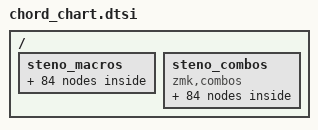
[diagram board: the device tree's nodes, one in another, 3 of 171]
#include "keypos.h"

/ {
    steno_macros {
      m_examples_: m_examples_ {
        compatible = "zmk,behavior-macro";
        #binding-cells = <0>;
        wait-ms = <0>;
        tap-ms = <10>;
        bindings = <&macro_tap &kp E &kp X &kp A &kp M &kp P &kp L &kp E &kp S &kp SPACE>;
      };

      m_example_: m_example_ {
        compatible = "zmk,behavior-macro";
        #binding-cells = <0>;
        wait-ms = <0>;
        tap-ms = <10>;
        bindings = <&macro_tap &kp E &kp X &kp A &kp M &kp P &kp L &kp E &kp SPACE>;
      };

      m_languages_: m_languages_ {
        compatible = "zmk,behavior-macro";
        #binding-cells = <0>;
        wait-ms = <0>;
        tap-ms = <10>;
        bindings = <&macro_tap &kp L &kp A &kp N &kp G &kp U &kp A &kp G &kp E &kp S &kp SPACE>;
      };

      m_language_: m_language_ {
        compatible = "zmk,behavior-macro";
        #binding-cells = <0>;
        wait-ms = <0>;
        tap-ms = <10>;
        bindings = <&macro_tap &kp L &kp A &kp N &kp G &kp U &kp A &kp G &kp E &kp SPACE>;
      };

      m_logical_: m_logical_ {
        compatible = "zmk,behavior-macro";
        #binding-cells = <0>;
        wait-ms = <0>;
        tap-ms = <10>;
        bindings = <&macro_tap &kp L &kp O &kp G &kp I &kp C &kp A &kp L &kp SPACE>;
      };

      m_whichever_: m_whichever_ {
        compatible = "zmk,behavior-macro";
        #binding-cells = <0>;
        wait-ms = <0>;
        tap-ms = <10>;
        bindings = <&macro_tap &kp W &kp H &kp I &kp C &kp H &kp E &kp V &kp E &kp R &kp SPACE>;
      };

      m_which_: m_which_ {
        compatible = "zmk,behavior-macro";
        #binding-cells = <0>;
        wait-ms = <0>;
        tap-ms = <10>;
        bindings = <&macro_tap &kp W &kp H &kp I &kp C &kp H &kp SPACE>;
      };

      m_screens_: m_screens_ {
        compatible = "zmk,behavior-macro";
        #binding-cells = <0>;
        wait-ms = <0>;
        tap-ms = <10>;
        bindings = <&macro_tap &kp S &kp C &kp R &kp E &kp E &kp N &kp S &kp SPACE>;
      };

      m_screened_: m_screened_ {
        compatible = "zmk,behavior-macro";
        #binding-cells = <0>;
        wait-ms = <0>;
        tap-ms = <10>;
        bindings = <&macro_tap &kp S &kp C &kp R &kp E &kp E &kp N &kp E &kp D &kp SPACE>;
      };

      m_screening_: m_screening_ {
        compatible = "zmk,behavior-macro";
        #binding-cells = <0>;
        wait-ms = <0>;
        tap-ms = <10>;
        bindings = <&macro_tap &kp S &kp C &kp R &kp E &kp E &kp N &kp I &kp N &kp G &kp SPACE>;
      };

      m_screen_: m_screen_ {
        compatible = "zmk,behavior-macro";
        #binding-cells = <0>;
        wait-ms = <0>;
        tap-ms = <10>;
        bindings = <&macro_tap &kp S &kp C &kp R &kp E &kp E &kp N &kp SPACE>;
      };

      m_sounding_: m_sounding_ {
        compatible = "zmk,behavior-macro";
        #binding-cells = <0>;
        wait-ms = <0>;
        tap-ms = <10>;
        bindings = <&macro_tap &kp S &kp O &kp U &kp N &kp D &kp I &kp N &kp G &kp SPACE>;
      };

      m_sounded_: m_sounded_ {
        compatible = "zmk,behavior-macro";
        #binding-cells = <0>;
        wait-ms = <0>;
        tap-ms = <10>;
        bindings = <&macro_tap &kp S &kp O &kp U &kp N &kp D &kp E &kp D &kp SPACE>;
      };

      m_sounds_: m_sounds_ {
        compatible = "zmk,behavior-macro";
        #binding-cells = <0>;
        wait-ms = <0>;
        tap-ms = <10>;
        bindings = <&macro_tap &kp S &kp O &kp U &kp N &kp D &kp S &kp SPACE>;
      };

      m_sound_: m_sound_ {
        compatible = "zmk,behavior-macro";
        #binding-cells = <0>;
        wait-ms = <0>;
        tap-ms = <10>;
        bindings = <&macro_tap &kp S &kp O &kp U &kp N &kp D &kp SPACE>;
      };

      m_since_: m_since_ {
        compatible = "zmk,behavior-macro";
        #binding-cells = <0>;
        wait-ms = <0>;
        tap-ms = <10>;
        bindings = <&macro_tap &kp S &kp I &kp N &kp C &kp E &kp SPACE>;
      };

      m_considered_: m_considered_ {
        compatible = "zmk,behavior-macro";
        #binding-cells = <0>;
        wait-ms = <0>;
        tap-ms = <10>;
        bindings = <&macro_tap &kp C &kp O &kp N &kp S &kp I &kp D &kp E &kp R &kp E &kp D &kp SPACE>;
      };

      m_coloring_: m_coloring_ {
        compatible = "zmk,behavior-macro";
        #binding-cells = <0>;
        wait-ms = <0>;
        tap-ms = <10>;
        bindings = <&macro_tap &kp C &kp O &kp L &kp O &kp R &kp I &kp N &kp G &kp SPACE>;
      };

      m_colored_: m_colored_ {
        compatible = "zmk,behavior-macro";
        #binding-cells = <0>;
        wait-ms = <0>;
        tap-ms = <10>;
        bindings = <&macro_tap &kp C &kp O &kp L &kp O &kp R &kp E &kp D &kp SPACE>;
      };

      m_colors_: m_colors_ {
        compatible = "zmk,behavior-macro";
        #binding-cells = <0>;
        wait-ms = <0>;
        tap-ms = <10>;
        bindings = <&macro_tap &kp C &kp O &kp L &kp O &kp R &kp S &kp SPACE>;
      };

      m_color_: m_color_ {
        compatible = "zmk,behavior-macro";
        #binding-cells = <0>;
        wait-ms = <0>;
        tap-ms = <10>;
        bindings = <&macro_tap &kp C &kp O &kp L &kp O &kp R &kp SPACE>;
      };

      m_distinguishing_: m_distinguishing_ {
        compatible = "zmk,behavior-macro";
        #binding-cells = <0>;
        wait-ms = <0>;
        tap-ms = <10>;
        bindings = <&macro_tap &kp D &kp I &kp S &kp T &kp I &kp N &kp G &kp U &kp I &kp S &kp H &kp I &kp N &kp G &kp SPACE>;
      };

      m_distinguishes_: m_distinguishes_ {
        compatible = "zmk,behavior-macro";
        #binding-cells = <0>;
        wait-ms = <0>;
        tap-ms = <10>;
        bindings = <&macro_tap &kp D &kp I &kp S &kp T &kp I &kp N &kp G &kp U &kp I &kp S &kp H &kp E &kp S &kp SPACE>;
      };

      m_distinguished_: m_distinguished_ {
        compatible = "zmk,behavior-macro";
        #binding-cells = <0>;
        wait-ms = <0>;
        tap-ms = <10>;
        bindings = <&macro_tap &kp D &kp I &kp S &kp T &kp I &kp N &kp G &kp U &kp I &kp S &kp H &kp E &kp D &kp SPACE>;
      };

      m_distinguish_: m_distinguish_ {
        compatible = "zmk,behavior-macro";
        #binding-cells = <0>;
        wait-ms = <0>;
        tap-ms = <10>;
        bindings = <&macro_tap &kp D &kp I &kp S &kp T &kp I &kp N &kp G &kp U &kp I &kp S &kp H &kp SPACE>;
      };

      m_intensely_: m_intensely_ {
        compatible = "zmk,behavior-macro";
        #binding-cells = <0>;
        wait-ms = <0>;
        tap-ms = <10>;
        bindings = <&macro_tap &kp I &kp N &kp T &kp E &kp N &kp S &kp E &kp L &kp Y &kp SPACE>;
      };

      m_intensity_: m_intensity_ {
        compatible = "zmk,behavior-macro";
        #binding-cells = <0>;
        wait-ms = <0>;
        tap-ms = <10>;
        bindings = <&macro_tap &kp I &kp N &kp T &kp E &kp N &kp S &kp I &kp T &kp Y &kp SPACE>;
      };

      m_intense_: m_intense_ {
        compatible = "zmk,behavior-macro";
        #binding-cells = <0>;
        wait-ms = <0>;
        tap-ms = <10>;
        bindings = <&macro_tap &kp I &kp N &kp T &kp E &kp N &kp S &kp E &kp SPACE>;
      };

      m_risks_: m_risks_ {
        compatible = "zmk,behavior-macro";
        #binding-cells = <0>;
        wait-ms = <0>;
        tap-ms = <10>;
        bindings = <&macro_tap &kp R &kp I &kp S &kp K &kp S &kp SPACE>;
      };

      m_risked_: m_risked_ {
        compatible = "zmk,behavior-macro";
        #binding-cells = <0>;
        wait-ms = <0>;
        tap-ms = <10>;
        bindings = <&macro_tap &kp R &kp I &kp S &kp K &kp E &kp D &kp SPACE>;
      };

      m_risking_: m_risking_ {
        compatible = "zmk,behavior-macro";
        #binding-cells = <0>;
        wait-ms = <0>;
        tap-ms = <10>;
        bindings = <&macro_tap &kp R &kp I &kp S &kp K &kp I &kp N &kp G &kp SPACE>;
      };

      m_risk_: m_risk_ {
        compatible = "zmk,behavior-macro";
        #binding-cells = <0>;
        wait-ms = <0>;
        tap-ms = <10>;
        bindings = <&macro_tap &kp R &kp I &kp S &kp K &kp SPACE>;
      };

      m_but_: m_but_ {
        compatible = "zmk,behavior-macro";
        #binding-cells = <0>;
        wait-ms = <0>;
        tap-ms = <10>;
        bindings = <&macro_tap &kp B &kp U &kp T &kp SPACE>;
      };

      m_genders_: m_genders_ {
        compatible = "zmk,behavior-macro";
        #binding-cells = <0>;
        wait-ms = <0>;
        tap-ms = <10>;
        bindings = <&macro_tap &kp G &kp E &kp N &kp D &kp E &kp R &kp S &kp SPACE>;
      };

      m_gender: m_gender {
        compatible = "zmk,behavior-macro";
        #binding-cells = <0>;
        wait-ms = <0>;
        tap-ms = <10>;
        bindings = <&macro_tap &kp G &kp E &kp N &kp D &kp E &kp R>;
      };

      m_Angelically_: m_Angelically_ {
        compatible = "zmk,behavior-macro";
        #binding-cells = <0>;
        wait-ms = <0>;
        tap-ms = <10>;
        bindings = <&macro_tap &kp LSHFT &kp A &kp LSHFT &kp N &kp G &kp E &kp L &kp I &kp C &kp A &kp L &kp L &kp Y &kp SPACE>;
      };

      m_Angelic_: m_Angelic_ {
        compatible = "zmk,behavior-macro";
        #binding-cells = <0>;
        wait-ms = <0>;
        tap-ms = <10>;
        bindings = <&macro_tap &kp LSHFT &kp A &kp LSHFT &kp N &kp G &kp E &kp L &kp I &kp C &kp SPACE>;
      };

      m_Angel_: m_Angel_ {
        compatible = "zmk,behavior-macro";
        #binding-cells = <0>;
        wait-ms = <0>;
        tap-ms = <10>;
        bindings = <&macro_tap &kp LSHFT &kp A &kp LSHFT &kp N &kp G &kp E &kp L &kp SPACE>;
      };

      m_Amiya's_: m_Amiya's_ {
        compatible = "zmk,behavior-macro";
        #binding-cells = <0>;
        wait-ms = <0>;
        tap-ms = <10>;
        bindings = <&macro_tap &kp LSHFT &kp A &kp LSHFT &kp M &kp I &kp Y &kp A &kp LSHFT &kp ' &kp LSHFT &kp S &kp SPACE>;
      };

      m_Amiya_: m_Amiya_ {
        compatible = "zmk,behavior-macro";
        #binding-cells = <0>;
        wait-ms = <0>;
        tap-ms = <10>;
        bindings = <&macro_tap &kp LSHFT &kp A &kp LSHFT &kp M &kp I &kp Y &kp A &kp SPACE>;
      };

      m_despressed_: m_despressed_ {
        compatible = "zmk,behavior-macro";
        #binding-cells = <0>;
        wait-ms = <0>;
        tap-ms = <10>;
        bindings = <&macro_tap &kp D &kp E &kp S &kp P &kp R &kp E &kp S &kp S &kp E &kp D &kp SPACE>;
      };

      m_depressing_: m_depressing_ {
        compatible = "zmk,behavior-macro";
        #binding-cells = <0>;
        wait-ms = <0>;
        tap-ms = <10>;
        bindings = <&macro_tap &kp D &kp E &kp P &kp R &kp E &kp S &kp S &kp I &kp N &kp G &kp SPACE>;
      };

      m_depress_: m_depress_ {
        compatible = "zmk,behavior-macro";
        #binding-cells = <0>;
        wait-ms = <0>;
        tap-ms = <10>;
        bindings = <&macro_tap &kp D &kp E &kp P &kp R &kp E &kp S &kp S &kp SPACE>;
      };

      m_desperate_: m_desperate_ {
        compatible = "zmk,behavior-macro";
        #binding-cells = <0>;
        wait-ms = <0>;
        tap-ms = <10>;
        bindings = <&macro_tap &kp D &kp E &kp S &kp P &kp E &kp R &kp A &kp T &kp E &kp SPACE>;
      };

      m_despair_: m_despair_ {
        compatible = "zmk,behavior-macro";
        #binding-cells = <0>;
        wait-ms = <0>;
        tap-ms = <10>;
        bindings = <&macro_tap &kp D &kp E &kp S &kp P &kp A &kp I &kp R &kp SPACE>;
      };

      m_desiring_: m_desiring_ {
        compatible = "zmk,behavior-macro";
        #binding-cells = <0>;
        wait-ms = <0>;
        tap-ms = <10>;
        bindings = <&macro_tap &kp D &kp E &kp S &kp I &kp R &kp I &kp N &kp G &kp SPACE>;
      };

      m_desire_: m_desire_ {
        compatible = "zmk,behavior-macro";
        #binding-cells = <0>;
        wait-ms = <0>;
        tap-ms = <10>;
        bindings = <&macro_tap &kp D &kp E &kp S &kp I &kp R &kp E &kp SPACE>;
      };

      m_throwing_: m_throwing_ {
        compatible = "zmk,behavior-macro";
        #binding-cells = <0>;
        wait-ms = <0>;
        tap-ms = <10>;
        bindings = <&macro_tap &kp T &kp H &kp R &kp O &kp W &kp I &kp N &kp G &kp SPACE>;
      };

      m_throws_: m_throws_ {
        compatible = "zmk,behavior-macro";
        #binding-cells = <0>;
        wait-ms = <0>;
        tap-ms = <10>;
        bindings = <&macro_tap &kp T &kp H &kp R &kp O &kp W &kp S &kp SPACE>;
      };

      m_throw_: m_throw_ {
        compatible = "zmk,behavior-macro";
        #binding-cells = <0>;
        wait-ms = <0>;
        tap-ms = <10>;
        bindings = <&macro_tap &kp T &kp H &kp R &kp O &kp W &kp SPACE>;
      };

      m_brought_: m_brought_ {
        compatible = "zmk,behavior-macro";
        #binding-cells = <0>;
        wait-ms = <0>;
        tap-ms = <10>;
        bindings = <&macro_tap &kp B &kp R &kp O &kp U &kp G &kp H &kp T &kp SPACE>;
      };

      m_bringing_: m_bringing_ {
        compatible = "zmk,behavior-macro";
        #binding-cells = <0>;
        wait-ms = <0>;
        tap-ms = <10>;
        bindings = <&macro_tap &kp B &kp R &kp I &kp N &kp G &kp I &kp N &kp G &kp SPACE>;
      };

      m_bring_: m_bring_ {
        compatible = "zmk,behavior-macro";
        #binding-cells = <0>;
        wait-ms = <0>;
        tap-ms = <10>;
        bindings = <&macro_tap &kp B &kp R &kp I &kp N &kp G &kp SPACE>;
      };

      m_looking_: m_looking_ {
        compatible = "zmk,behavior-macro";
        #binding-cells = <0>;
        wait-ms = <0>;
        tap-ms = <10>;
        bindings = <&macro_tap &kp L &kp O &kp O &kp K &kp I &kp N &kp G &kp SPACE>;
      };

      m_looked_: m_looked_ {
        compatible = "zmk,behavior-macro";
        #binding-cells = <0>;
        wait-ms = <0>;
        tap-ms = <10>;
        bindings = <&macro_tap &kp L &kp O &kp O &kp K &kp E &kp D &kp SPACE>;
      };

      m_look_: m_look_ {
        compatible = "zmk,behavior-macro";
        #binding-cells = <0>;
        wait-ms = <0>;
        tap-ms = <10>;
        bindings = <&macro_tap &kp L &kp O &kp O &kp K &kp SPACE>;
      };

      m_forgiving_: m_forgiving_ {
        compatible = "zmk,behavior-macro";
        #binding-cells = <0>;
        wait-ms = <0>;
        tap-ms = <10>;
        bindings = <&macro_tap &kp F &kp O &kp R &kp G &kp I &kp V &kp I &kp N &kp G &kp SPACE>;
      };

      m_forgive_: m_forgive_ {
        compatible = "zmk,behavior-macro";
        #binding-cells = <0>;
        wait-ms = <0>;
        tap-ms = <10>;
        bindings = <&macro_tap &kp F &kp O &kp R &kp G &kp I &kp V &kp E &kp SPACE>;
      };

      m_of_: m_of_ {
        compatible = "zmk,behavior-macro";
        #binding-cells = <0>;
        wait-ms = <0>;
        tap-ms = <10>;
        bindings = <&macro_tap &kp O &kp F &kp SPACE>;
      };

      m_relat: m_relat {
        compatible = "zmk,behavior-macro";
        #binding-cells = <0>;
        wait-ms = <0>;
        tap-ms = <10>;
        bindings = <&macro_tap &kp R &kp E &kp L &kp A &kp T>;
      };

      m_inter: m_inter {
        compatible = "zmk,behavior-macro";
        #binding-cells = <0>;
        wait-ms = <0>;
        tap-ms = <10>;
        bindings = <&macro_tap &kp I &kp N &kp T &kp E &kp R>;
      };

      m_powering_: m_powering_ {
        compatible = "zmk,behavior-macro";
        #binding-cells = <0>;
        wait-ms = <0>;
        tap-ms = <10>;
        bindings = <&macro_tap &kp P &kp O &kp W &kp E &kp R &kp I &kp N &kp G &kp SPACE>;
      };

      m_powered_: m_powered_ {
        compatible = "zmk,behavior-macro";
        #binding-cells = <0>;
        wait-ms = <0>;
        tap-ms = <10>;
        bindings = <&macro_tap &kp P &kp O &kp W &kp E &kp R &kp E &kp D &kp SPACE>;
      };

      m_powers_: m_powers_ {
        compatible = "zmk,behavior-macro";
        #binding-cells = <0>;
        wait-ms = <0>;
        tap-ms = <10>;
        bindings = <&macro_tap &kp P &kp O &kp W &kp E &kp R &kp S &kp SPACE>;
      };

      m_power_: m_power_ {
        compatible = "zmk,behavior-macro";
        #binding-cells = <0>;
        wait-ms = <0>;
        tap-ms = <10>;
        bindings = <&macro_tap &kp P &kp O &kp W &kp E &kp R &kp SPACE>;
      };

      m_seeing_: m_seeing_ {
        compatible = "zmk,behavior-macro";
        #binding-cells = <0>;
        wait-ms = <0>;
        tap-ms = <10>;
        bindings = <&macro_tap &kp S &kp E &kp E &kp I &kp N &kp G &kp SPACE>;
      };

      m_seen_: m_seen_ {
        compatible = "zmk,behavior-macro";
        #binding-cells = <0>;
        wait-ms = <0>;
        tap-ms = <10>;
        bindings = <&macro_tap &kp S &kp E &kp E &kp N &kp SPACE>;
      };

      m_sees_: m_sees_ {
        compatible = "zmk,behavior-macro";
        #binding-cells = <0>;
        wait-ms = <0>;
        tap-ms = <10>;
        bindings = <&macro_tap &kp S &kp E &kp E &kp S &kp SPACE>;
      };

      m_see_: m_see_ {
        compatible = "zmk,behavior-macro";
        #binding-cells = <0>;
        wait-ms = <0>;
        tap-ms = <10>;
        bindings = <&macro_tap &kp S &kp E &kp E &kp SPACE>;
      };

      m_ness_: m_ness_ {
        compatible = "zmk,behavior-macro";
        #binding-cells = <0>;
        wait-ms = <0>;
        tap-ms = <10>;
        bindings = <&macro_tap &kp N &kp E &kp S &kp S &kp SPACE>;
      };

      m_reflecting_: m_reflecting_ {
        compatible = "zmk,behavior-macro";
        #binding-cells = <0>;
        wait-ms = <0>;
        tap-ms = <10>;
        bindings = <&macro_tap &kp R &kp E &kp F &kp L &kp E &kp C &kp T &kp I &kp N &kp G &kp SPACE>;
      };

      m_reflected_: m_reflected_ {
        compatible = "zmk,behavior-macro";
        #binding-cells = <0>;
        wait-ms = <0>;
        tap-ms = <10>;
        bindings = <&macro_tap &kp R &kp E &kp F &kp L &kp E &kp C &kp T &kp E &kp D &kp SPACE>;
      };

      m_reflects_: m_reflects_ {
        compatible = "zmk,behavior-macro";
        #binding-cells = <0>;
        wait-ms = <0>;
        tap-ms = <10>;
        bindings = <&macro_tap &kp R &kp E &kp F &kp L &kp E &kp C &kp T &kp S &kp SPACE>;
      };

      m_reflect_: m_reflect_ {
        compatible = "zmk,behavior-macro";
        #binding-cells = <0>;
        wait-ms = <0>;
        tap-ms = <10>;
        bindings = <&macro_tap &kp R &kp E &kp F &kp L &kp E &kp C &kp T &kp SPACE>;
      };

      m_thus_: m_thus_ {
        compatible = "zmk,behavior-macro";
        #binding-cells = <0>;
        wait-ms = <0>;
        tap-ms = <10>;
        bindings = <&macro_tap &kp T &kp H &kp U &kp S &kp SPACE>;
      };

      m_too_: m_too_ {
        compatible = "zmk,behavior-macro";
        #binding-cells = <0>;
        wait-ms = <0>;
        tap-ms = <10>;
        bindings = <&macro_tap &kp T &kp O &kp O &kp SPACE>;
      };

      m_to_: m_to_ {
        compatible = "zmk,behavior-macro";
        #binding-cells = <0>;
        wait-ms = <0>;
        tap-ms = <10>;
        bindings = <&macro_tap &kp T &kp O &kp SPACE>;
      };

      m_the_: m_the_ {
        compatible = "zmk,behavior-macro";
        #binding-cells = <0>;
        wait-ms = <0>;
        tap-ms = <10>;
        bindings = <&macro_tap &kp T &kp H &kp E &kp SPACE>;
      };

      m_toward: m_toward {
        compatible = "zmk,behavior-macro";
        #binding-cells = <0>;
        wait-ms = <0>;
        tap-ms = <10>;
        bindings = <&macro_tap &kp T &kp O &kp W &kp A &kp R &kp D>;
      };

      m_tendenc: m_tendenc {
        compatible = "zmk,behavior-macro";
        #binding-cells = <0>;
        wait-ms = <0>;
        tap-ms = <10>;
        bindings = <&macro_tap &kp T &kp E &kp N &kp D &kp E &kp N &kp C>;
      };

      m_similar: m_similar {
        compatible = "zmk,behavior-macro";
        #binding-cells = <0>;
        wait-ms = <0>;
        tap-ms = <10>;
        bindings = <&macro_tap &kp S &kp I &kp M &kp I &kp L &kp A &kp R>;
      };

      m_he: m_he {
        compatible = "zmk,behavior-macro";
        #binding-cells = <0>;
        wait-ms = <0>;
        tap-ms = <10>;
        bindings = <&macro_tap &kp H &kp E>;
      };

      m_she: m_she {
        compatible = "zmk,behavior-macro";
        #binding-cells = <0>;
        wait-ms = <0>;
        tap-ms = <10>;
        bindings = <&macro_tap &kp S &kp H &kp E>;
      };

      m_suffer: m_suffer {
        compatible = "zmk,behavior-macro";
        #binding-cells = <0>;
        wait-ms = <0>;
        tap-ms = <10>;
        bindings = <&macro_tap &kp S &kp U &kp F &kp F &kp E &kp R>;
      };


    };

    steno_combos {
      compatible = "zmk,combos";
      c_examples_ {
        timeout-ms = <50>;
        key-positions = <P_X P_A P_M P_P P_L P_COMMA>;
        bindings = <&m_examples_>;
        layers = <0>;
      };

      c_example_ {
        timeout-ms = <50>;
        key-positions = <P_X P_A P_M P_P P_L>;
        bindings = <&m_example_>;
        layers = <0>;
      };

      c_languages_ {
        timeout-ms = <50>;
        key-positions = <P_L P_A P_N P_G P_COMMA>;
        bindings = <&m_languages_>;
        layers = <0>;
      };

      c_language_ {
        timeout-ms = <50>;
        key-positions = <P_L P_A P_N P_G>;
        bindings = <&m_language_>;
        layers = <0>;
      };

      c_logical_ {
        timeout-ms = <50>;
        key-positions = <P_L P_O P_G P_I P_C P_SEMI>;
        bindings = <&m_logical_>;
        layers = <0>;
      };

      c_whichever_ {
        timeout-ms = <50>;
        key-positions = <P_W P_I P_C P_H P_E P_V P_R>;
        bindings = <&m_whichever_>;
        layers = <0>;
      };

      c_which_ {
        timeout-ms = <50>;
        key-positions = <P_W P_I P_C P_H>;
        bindings = <&m_which_>;
        layers = <0>;
      };

      c_screens_ {
        timeout-ms = <50>;
        key-positions = <P_S P_C P_R P_I P_N P_COMMA>;
        bindings = <&m_screens_>;
        layers = <0>;
      };

      c_screened_ {
        timeout-ms = <50>;
        key-positions = <P_S P_C P_R P_I P_N P_D>;
        bindings = <&m_screened_>;
        layers = <0>;
      };

      c_screening_ {
        timeout-ms = <50>;
        key-positions = <P_S P_C P_R P_I P_N P_SEMI>;
        bindings = <&m_screening_>;
        layers = <0>;
      };

      c_screen_ {
        timeout-ms = <50>;
        key-positions = <P_S P_C P_R P_I P_N>;
        bindings = <&m_screen_>;
        layers = <0>;
      };

      c_sounding_ {
        timeout-ms = <50>;
        key-positions = <P_S P_O P_U P_N P_D P_SEMI>;
        bindings = <&m_sounding_>;
        layers = <0>;
      };

      c_sounded_ {
        timeout-ms = <50>;
        key-positions = <P_S P_O P_U P_N P_D P_DOT>;
        bindings = <&m_sounded_>;
        layers = <0>;
      };

      c_sounds_ {
        timeout-ms = <50>;
        key-positions = <P_S P_O P_U P_N P_D P_COMMA>;
        bindings = <&m_sounds_>;
        layers = <0>;
      };

      c_sound_ {
        timeout-ms = <50>;
        key-positions = <P_S P_O P_U P_N P_D>;
        bindings = <&m_sound_>;
        layers = <0>;
      };

      c_since_ {
        timeout-ms = <50>;
        key-positions = <P_S P_I P_N P_C>;
        bindings = <&m_since_>;
        layers = <0>;
      };

      c_considered_ {
        timeout-ms = <50>;
        key-positions = <P_C P_O P_N P_S P_D>;
        bindings = <&m_considered_>;
        layers = <0>;
      };

      c_coloring_ {
        timeout-ms = <50>;
        key-positions = <P_C P_O P_L P_R P_SEMI>;
        bindings = <&m_coloring_>;
        layers = <0>;
      };

      c_colored_ {
        timeout-ms = <50>;
        key-positions = <P_C P_O P_L P_R P_D>;
        bindings = <&m_colored_>;
        layers = <0>;
      };

      c_colors_ {
        timeout-ms = <50>;
        key-positions = <P_C P_O P_L P_R P_COMMA>;
        bindings = <&m_colors_>;
        layers = <0>;
      };

      c_color_ {
        timeout-ms = <50>;
        key-positions = <P_C P_O P_L P_R>;
        bindings = <&m_color_>;
        layers = <0>;
      };

      c_distinguishing_ {
        timeout-ms = <50>;
        key-positions = <P_D P_I P_S P_T P_G P_H P_SEMI>;
        bindings = <&m_distinguishing_>;
        layers = <0>;
      };

      c_distinguishes_ {
        timeout-ms = <50>;
        key-positions = <P_D P_I P_S P_T P_G P_H P_COMMA>;
        bindings = <&m_distinguishes_>;
        layers = <0>;
      };

      c_distinguished_ {
        timeout-ms = <50>;
        key-positions = <P_D P_I P_S P_T P_G P_H P_DOT>;
        bindings = <&m_distinguished_>;
        layers = <0>;
      };

      c_distinguish_ {
        timeout-ms = <50>;
        key-positions = <P_D P_I P_S P_T P_G P_H>;
        bindings = <&m_distinguish_>;
        layers = <0>;
      };

      c_intensely_ {
        timeout-ms = <50>;
        key-positions = <P_I P_N P_T P_E P_S P_L P_Y>;
        bindings = <&m_intensely_>;
        layers = <0>;
      };

      c_intensity_ {
        timeout-ms = <50>;
        key-positions = <P_I P_N P_T P_E P_S P_Y>;
        bindings = <&m_intensity_>;
        layers = <0>;
      };

      c_intense_ {
        timeout-ms = <50>;
        key-positions = <P_I P_N P_T P_E P_S>;
        bindings = <&m_intense_>;
        layers = <0>;
      };

      c_risks_ {
        timeout-ms = <50>;
        key-positions = <P_R P_S P_K P_COMMA>;
        bindings = <&m_risks_>;
        layers = <0>;
      };

      c_risked_ {
        timeout-ms = <50>;
        key-positions = <P_R P_S P_K P_D>;
        bindings = <&m_risked_>;
        layers = <0>;
      };

      c_risking_ {
        timeout-ms = <50>;
        key-positions = <P_R P_S P_K P_SEMI>;
        bindings = <&m_risking_>;
        layers = <0>;
      };

      c_risk_ {
        timeout-ms = <50>;
        key-positions = <P_R P_S P_K>;
        bindings = <&m_risk_>;
        layers = <0>;
      };

      c_but_ {
        timeout-ms = <50>;
        key-positions = <P_B P_U P_T>;
        bindings = <&m_but_>;
        layers = <0>;
      };

      c_genders_ {
        timeout-ms = <50>;
        key-positions = <P_G P_E P_N P_D P_R P_COMMA>;
        bindings = <&m_genders_>;
        layers = <0>;
      };

      c_gender {
        timeout-ms = <50>;
        key-positions = <P_G P_E P_N P_D P_R>;
        bindings = <&m_gender>;
        layers = <0>;
      };

      c_Angelically_ {
        timeout-ms = <50>;
        key-positions = <P_A P_M P_I P_Y P_SEMI>;
        bindings = <&m_Angelically_>;
        layers = <0>;
      };

      c_Angelic_ {
        timeout-ms = <50>;
        key-positions = <P_A P_M P_I P_SEMI>;
        bindings = <&m_Angelic_>;
        layers = <0>;
      };

      c_Angel_ {
        timeout-ms = <50>;
        key-positions = <P_A P_M P_I P_L>;
        bindings = <&m_Angel_>;
        layers = <0>;
      };

      c_Amiya's_ {
        timeout-ms = <50>;
        key-positions = <P_A P_M P_I P_Y P_COMMA>;
        bindings = <&m_Amiya's_>;
        layers = <0>;
      };

      c_Amiya_ {
        timeout-ms = <50>;
        key-positions = <P_A P_M P_I P_Y>;
        bindings = <&m_Amiya_>;
        layers = <0>;
      };

      c_despressed_ {
        timeout-ms = <50>;
        key-positions = <P_D P_E P_P P_R P_S P_DOT>;
        bindings = <&m_despressed_>;
        layers = <0>;
      };

      c_depressing_ {
        timeout-ms = <50>;
        key-positions = <P_D P_E P_P P_R P_S P_SEMI>;
        bindings = <&m_depressing_>;
        layers = <0>;
      };

      c_depress_ {
        timeout-ms = <50>;
        key-positions = <P_D P_E P_P P_R P_S>;
        bindings = <&m_depress_>;
        layers = <0>;
      };

      c_desperate_ {
        timeout-ms = <50>;
        key-positions = <P_D P_E P_P P_R P_T>;
        bindings = <&m_desperate_>;
        layers = <0>;
      };

      c_despair_ {
        timeout-ms = <50>;
        key-positions = <P_D P_E P_S P_P P_E P_R>;
        bindings = <&m_despair_>;
        layers = <0>;
      };

      c_desiring_ {
        timeout-ms = <50>;
        key-positions = <P_D P_E P_Z P_I P_R P_SEMI>;
        bindings = <&m_desiring_>;
        layers = <0>;
      };

      c_desire_ {
        timeout-ms = <50>;
        key-positions = <P_D P_E P_Z P_I P_R>;
        bindings = <&m_desire_>;
        layers = <0>;
      };

      c_throwing_ {
        timeout-ms = <50>;
        key-positions = <P_T P_H P_R P_O P_SEMI>;
        bindings = <&m_throwing_>;
        layers = <0>;
      };

      c_throws_ {
        timeout-ms = <50>;
        key-positions = <P_T P_H P_R P_O P_COMMA>;
        bindings = <&m_throws_>;
        layers = <0>;
      };

      c_throw_ {
        timeout-ms = <50>;
        key-positions = <P_T P_H P_R P_O>;
        bindings = <&m_throw_>;
        layers = <0>;
      };

      c_brought_ {
        timeout-ms = <50>;
        key-positions = <P_B P_R P_O P_T>;
        bindings = <&m_brought_>;
        layers = <0>;
      };

      c_bringing_ {
        timeout-ms = <50>;
        key-positions = <P_B P_R P_SEMI P_DOT>;
        bindings = <&m_bringing_>;
        layers = <0>;
      };

      c_bring_ {
        timeout-ms = <50>;
        key-positions = <P_B P_R P_SEMI>;
        bindings = <&m_bring_>;
        layers = <0>;
      };

      c_looking_ {
        timeout-ms = <50>;
        key-positions = <P_L P_O P_U P_K P_SEMI>;
        bindings = <&m_looking_>;
        layers = <0>;
      };

      c_looked_ {
        timeout-ms = <50>;
        key-positions = <P_L P_O P_U P_K P_D>;
        bindings = <&m_looked_>;
        layers = <0>;
      };

      c_look_ {
        timeout-ms = <50>;
        key-positions = <P_L P_O P_U P_K>;
        bindings = <&m_look_>;
        layers = <0>;
      };

      c_forgiving_ {
        timeout-ms = <50>;
        key-positions = <P_F P_O P_R P_G P_I P_V P_SEMI>;
        bindings = <&m_forgiving_>;
        layers = <0>;
      };

      c_forgive_ {
        timeout-ms = <50>;
        key-positions = <P_F P_O P_R P_G P_I P_V>;
        bindings = <&m_forgive_>;
        layers = <0>;
      };

      c_of_ {
        timeout-ms = <50>;
        key-positions = <P_U P_V>;
        bindings = <&m_of_>;
        layers = <0>;
      };

      c_relat {
        timeout-ms = <50>;
        key-positions = <P_R P_E P_L P_A P_T>;
        bindings = <&m_relat>;
        layers = <0>;
      };

      c_inter {
        timeout-ms = <50>;
        key-positions = <P_I P_N P_T P_R>;
        bindings = <&m_inter>;
        layers = <0>;
      };

      c_powering_ {
        timeout-ms = <50>;
        key-positions = <P_P P_W P_R P_SEMI>;
        bindings = <&m_powering_>;
        layers = <0>;
      };

      c_powered_ {
        timeout-ms = <50>;
        key-positions = <P_P P_W P_R P_D>;
        bindings = <&m_powered_>;
        layers = <0>;
      };

      c_powers_ {
        timeout-ms = <50>;
        key-positions = <P_P P_W P_R P_COMMA>;
        bindings = <&m_powers_>;
        layers = <0>;
      };

      c_power_ {
        timeout-ms = <50>;
        key-positions = <P_P P_W P_R>;
        bindings = <&m_power_>;
        layers = <0>;
      };

      c_seeing_ {
        timeout-ms = <50>;
        key-positions = <P_S P_E P_DOT P_SEMI>;
        bindings = <&m_seeing_>;
        layers = <0>;
      };

      c_seen_ {
        timeout-ms = <50>;
        key-positions = <P_S P_E P_DOT P_N>;
        bindings = <&m_seen_>;
        layers = <0>;
      };

      c_sees_ {
        timeout-ms = <50>;
        key-positions = <P_S P_E P_DOT P_COMMA>;
        bindings = <&m_sees_>;
        layers = <0>;
      };

      c_see_ {
        timeout-ms = <50>;
        key-positions = <P_S P_E P_DOT>;
        bindings = <&m_see_>;
        layers = <0>;
      };

      c_ness_ {
        timeout-ms = <50>;
        key-positions = <P_N P_E P_S P_DOT>;
        bindings = <&m_ness_>;
        layers = <0>;
      };

      c_reflecting_ {
        timeout-ms = <50>;
        key-positions = <P_R P_E P_F P_L P_C P_T P_SEMI>;
        bindings = <&m_reflecting_>;
        layers = <0>;
      };

      c_reflected_ {
        timeout-ms = <50>;
        key-positions = <P_R P_E P_F P_L P_C P_T P_D>;
        bindings = <&m_reflected_>;
        layers = <0>;
      };

      c_reflects_ {
        timeout-ms = <50>;
        key-positions = <P_R P_E P_F P_L P_C P_T P_COMMA>;
        bindings = <&m_reflects_>;
        layers = <0>;
      };

      c_reflect_ {
        timeout-ms = <50>;
        key-positions = <P_R P_E P_F P_L P_C P_T>;
        bindings = <&m_reflect_>;
        layers = <0>;
      };

      c_thus_ {
        timeout-ms = <50>;
        key-positions = <P_T P_H P_U P_S>;
        bindings = <&m_thus_>;
        layers = <0>;
      };

      c_too_ {
        timeout-ms = <50>;
        key-positions = <P_T P_O P_DOT>;
        bindings = <&m_too_>;
        layers = <0>;
      };

      c_to_ {
        timeout-ms = <50>;
        key-positions = <P_T P_O>;
        bindings = <&m_to_>;
        layers = <0>;
      };

      c_the_ {
        timeout-ms = <50>;
        key-positions = <P_T P_H P_E>;
        bindings = <&m_the_>;
        layers = <0>;
      };

      c_toward {
        timeout-ms = <50>;
        key-positions = <P_T P_O P_W P_A P_R P_D>;
        bindings = <&m_toward>;
        layers = <0>;
      };

      c_tendenc {
        timeout-ms = <50>;
        key-positions = <P_T P_E P_N P_D P_C>;
        bindings = <&m_tendenc>;
        layers = <0>;
      };

      c_similar {
        timeout-ms = <50>;
        key-positions = <P_S P_I P_M P_L P_R>;
        bindings = <&m_similar>;
        layers = <0>;
      };

      c_he {
        timeout-ms = <50>;
        key-positions = <P_H P_E>;
        bindings = <&m_he>;
        layers = <0>;
      };

      c_she {
        timeout-ms = <50>;
        key-positions = <P_S P_H P_E>;
        bindings = <&m_she>;
        layers = <0>;
      };

      c_suffer {
        timeout-ms = <50>;
        key-positions = <P_S P_U P_F P_R>;
        bindings = <&m_suffer>;
        layers = <0>;
      };

  
    };
};
